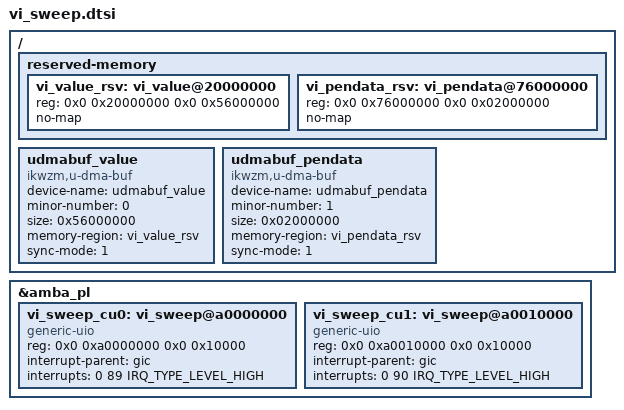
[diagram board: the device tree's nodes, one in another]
/*
 * vi_sweep.dtsi — Petalinux device tree overlay for Phase 3 driver
 *
 * Provides two UIO nodes (one per vi_sweep compute unit) and two
 * u-dma-buf regions backed by reserved CMA memory for the value
 * table (R/W) and the combined penalty+trans buffer (RO).
 *
 * SPI numbers for pl_ps_irq0[1:0] must be verified from the Vivado
 * IP Integrator address editor after regenerating the bitstream.
 * See fpga/vivado/ultra96v2/irq_notes.txt for placeholders.
 */

/include/ "dt-bindings/interrupt-controller/irq.h"

/ {
    reserved-memory {
        #address-cells = <2>;
        #size-cells    = <2>;
        ranges;

        /* Value table: ~1.375 GB, R/W */
        vi_value_rsv: vi_value@20000000 {
            reg = <0x0 0x20000000  0x0 0x56000000>;
            no-map;
        };

        /* Penalty + Trans: 32 MB, RO */
        vi_pendata_rsv: vi_pendata@76000000 {
            reg = <0x0 0x76000000  0x0 0x02000000>;
            no-map;
        };
    };

    udmabuf_value {
        compatible = "ikwzm,u-dma-buf";
        device-name = "udmabuf_value";
        minor-number = <0>;
        size = <0x56000000>;
        memory-region = <&vi_value_rsv>;
        sync-mode = <1>;  /* SYNC_MODE_NONCACHED */
    };

    udmabuf_pendata {
        compatible = "ikwzm,u-dma-buf";
        device-name = "udmabuf_pendata";
        minor-number = <1>;
        size = <0x02000000>;
        memory-region = <&vi_pendata_rsv>;
        sync-mode = <1>;
    };
};

&amba_pl {
    vi_sweep_cu0: vi_sweep@a0000000 {
        compatible = "generic-uio";
        reg = <0x0 0xa0000000 0x0 0x10000>;
        interrupt-parent = <&gic>;
        /* pl_ps_irq0[0]; confirm SPI number from Vivado */
        interrupts = <0 89 IRQ_TYPE_LEVEL_HIGH>;
    };

    vi_sweep_cu1: vi_sweep@a0010000 {
        compatible = "generic-uio";
        reg = <0x0 0xa0010000 0x0 0x10000>;
        interrupt-parent = <&gic>;
        /* pl_ps_irq0[1]; confirm SPI number from Vivado */
        interrupts = <0 90 IRQ_TYPE_LEVEL_HIGH>;
    };
};
